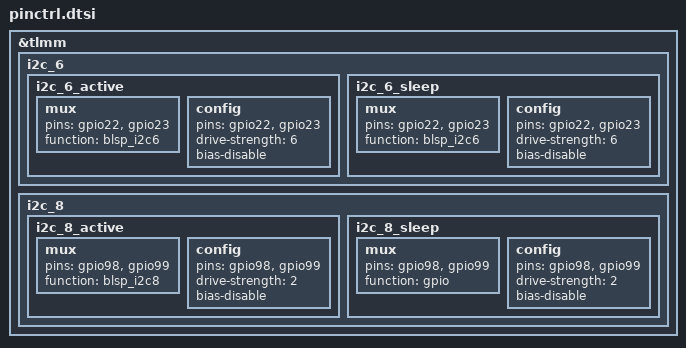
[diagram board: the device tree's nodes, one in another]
&tlmm {
		i2c_6 {
			i2c_6_active: i2c_6_active {
				mux {
					pins = "gpio22", "gpio23";
					function = "blsp_i2c6";
				};
				config {
					pins = "gpio22", "gpio23";
					drive-strength = <6>;
					bias-disable;
				};
			};

			i2c_6_sleep: i2c_6_sleep {
				mux {
					pins = "gpio22", "gpio23";
					function = "blsp_i2c6";
				};

				config {
					pins = "gpio22", "gpio23";
					drive-strength = <6>;
					bias-disable;
				};
			};
		};
		
		i2c_8 {

			i2c_8_active: i2c_8_active {
				mux {
					pins = "gpio98", "gpio99";
					function = "blsp_i2c8";
				};

				config {
					pins = "gpio98", "gpio99";
					drive-strength = <2>;
					bias-disable;
				};
			};

			i2c_8_sleep: i2c_8_sleep {
				mux {
					pins = "gpio98", "gpio99";
					function = "gpio";
				};

				config {
					pins = "gpio98", "gpio99";
					drive-strength = <2>;
					bias-disable;
				};
			};
		};
	};
